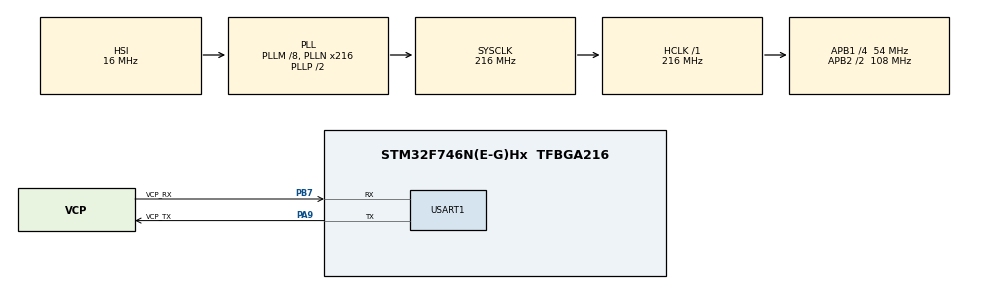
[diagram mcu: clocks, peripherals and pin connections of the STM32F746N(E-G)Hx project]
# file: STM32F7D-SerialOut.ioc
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Mcu.Family=STM32F7
Mcu.Name=STM32F746N(E-G)Hx
Mcu.Package=TFBGA216
NVIC.PriorityGroup=NVIC_PRIORITYGROUP_4
PA13.Mode=Trace-Asynchronous_SW
PA13.Signal=SYS_JTMS-SWDIO
PA14.Mode=Trace-Asynchronous_SW
PA14.Signal=SYS_JTCK-SWCLK
PA9.GPIO_Label=VCP_TX
PA9.Mode=Asynchronous
PA9.Signal=USART1_TX
PB3.Mode=Trace-Asynchronous_SW
PB3.Signal=SYS_JTDO-SWO
PB7.GPIO_Label=VCP_RX
PB7.Mode=Asynchronous
PB7.Signal=USART1_RX
ProjectManager.TargetToolchain=SW4STM32
RCC.AHBFreq_Value=216000000
RCC.APB1CLKDivider=RCC_HCLK_DIV4
RCC.APB1Freq_Value=54000000
RCC.APB1TimFreq_Value=108000000
RCC.APB2CLKDivider=RCC_HCLK_DIV2
RCC.APB2Freq_Value=108000000
RCC.APB2TimFreq_Value=216000000
RCC.CortexFreq_Value=216000000
RCC.HCLKFreq_Value=216000000
RCC.HSE_VALUE=25000000
RCC.HSI_VALUE=16000000
RCC.LSE_VALUE=32768
RCC.PLLM=8
RCC.PLLN=216
RCC.PLLQ=7
RCC.SYSCLKFreq_VALUE=216000000
RCC.SYSCLKSource=RCC_SYSCLKSOURCE_PLLCLK
RCC.USBFreq_Value=61714285.71428572
RCC.VCOOutputFreq_Value=432000000
board=STM32F746G-DISCO

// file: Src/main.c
/**
  ******************************************************************************
  * File Name          : main.c
  * Description        : Main program body
  ******************************************************************************
  *
  * COPYRIGHT(c) 2015 STMicroelectronics
  *
  * Redistribution and use in source and binary forms, with or without modification,
  * are permitted provided that the following conditions are met:
  *   1. Redistributions of source code must retain the above copyright notice,
  *      this list of conditions and the following disclaimer.
  *   2. Redistributions in binary form must reproduce the above copyright notice,
  *      this list of conditions and the following disclaimer in the documentation
  *      and/or other materials provided with the distribution.
  *   3. Neither the name of STMicroelectronics nor the names of its contributors
  *      may be used to endorse or promote products derived from this software
  *      without specific prior written permission.
  *
  * THIS SOFTWARE IS PROVIDED BY THE COPYRIGHT HOLDERS AND CONTRIBUTORS "AS IS"
  * AND ANY EXPRESS OR IMPLIED WARRANTIES, INCLUDING, BUT NOT LIMITED TO, THE
  * IMPLIED WARRANTIES OF MERCHANTABILITY AND FITNESS FOR A PARTICULAR PURPOSE ARE
  * DISCLAIMED. IN NO EVENT SHALL THE COPYRIGHT HOLDER OR CONTRIBUTORS BE LIABLE
  * FOR ANY DIRECT, INDIRECT, INCIDENTAL, SPECIAL, EXEMPLARY, OR CONSEQUENTIAL
  * DAMAGES (INCLUDING, BUT NOT LIMITED TO, PROCUREMENT OF SUBSTITUTE GOODS OR
  * SERVICES; LOSS OF USE, DATA, OR PROFITS; OR BUSINESS INTERRUPTION) HOWEVER
  * CAUSED AND ON ANY THEORY OF LIABILITY, WHETHER IN CONTRACT, STRICT LIABILITY,
  * OR TORT (INCLUDING NEGLIGENCE OR OTHERWISE) ARISING IN ANY WAY OUT OF THE USE
  * OF THIS SOFTWARE, EVEN IF ADVISED OF THE POSSIBILITY OF SUCH DAMAGE.
  *
  ******************************************************************************
  */
#include "stm32f7xx_hal.h"

UART_HandleTypeDef huart1;

/* USER CODE BEGIN PV */
/* Private variables ---------------------------------------------------------*/

/* USER CODE END PV */

void SystemClock_Config(void);
static void MX_GPIO_Init(void);
static void MX_USART1_UART_Init(void);

/* USER CODE BEGIN PFP */
/* Private function prototypes -----------------------------------------------*/

/* USER CODE END PFP */

int main(void)
{

  /* MCU Configuration----------------------------------------------------------*/

  /* Reset of all peripherals, Initializes the Flash interface and the Systick. */
  HAL_Init();

  /* Configure the system clock */
  SystemClock_Config();

  /* Initialize all configured peripherals */
  MX_GPIO_Init();
  MX_USART1_UART_Init();

  /* Infinite loop */
  /* USER CODE BEGIN WHILE */
  char output[3] = {'c', 'h', 'r'};
  int ch = 'c';
  while (1)
  {
  /* USER CODE END WHILE */
	  //HAL_UART_Transmit(&huart1, output, 3, 1000);
	  char str[32];
	  HAL_UART_Transmit(&huart1, (uint8_t *)&ch, 1, 0xFFFF); // As a pointer, with a length
  }

}

/** System Clock Configuration
*/
void SystemClock_Config(void)
{

  RCC_OscInitTypeDef RCC_OscInitStruct;
  RCC_ClkInitTypeDef RCC_ClkInitStruct;
  RCC_PeriphCLKInitTypeDef PeriphClkInitStruct;

  __PWR_CLK_ENABLE();

  __HAL_PWR_VOLTAGESCALING_CONFIG(PWR_REGULATOR_VOLTAGE_SCALE1);

  RCC_OscInitStruct.OscillatorType = RCC_OSCILLATORTYPE_HSI;
  RCC_OscInitStruct.HSIState = RCC_HSI_ON;
  RCC_OscInitStruct.HSICalibrationValue = 16;
  RCC_OscInitStruct.PLL.PLLState = RCC_PLL_ON;
  RCC_OscInitStruct.PLL.PLLSource = RCC_PLLSOURCE_HSI;
  RCC_OscInitStruct.PLL.PLLM = 8;
  RCC_OscInitStruct.PLL.PLLN = 216;
  RCC_OscInitStruct.PLL.PLLP = RCC_PLLP_DIV2;
  RCC_OscInitStruct.PLL.PLLQ = 7;
  HAL_RCC_OscConfig(&RCC_OscInitStruct);

  HAL_PWREx_ActivateOverDrive();

  RCC_ClkInitStruct.ClockType = RCC_CLOCKTYPE_HCLK|RCC_CLOCKTYPE_SYSCLK
                              |RCC_CLOCKTYPE_PCLK1|RCC_CLOCKTYPE_PCLK2;
  RCC_ClkInitStruct.SYSCLKSource = RCC_SYSCLKSOURCE_PLLCLK;
  RCC_ClkInitStruct.AHBCLKDivider = RCC_SYSCLK_DIV1;
  RCC_ClkInitStruct.APB1CLKDivider = RCC_HCLK_DIV4;
  RCC_ClkInitStruct.APB2CLKDivider = RCC_HCLK_DIV2;
  HAL_RCC_ClockConfig(&RCC_ClkInitStruct, FLASH_LATENCY_7);

  PeriphClkInitStruct.PeriphClockSelection = RCC_PERIPHCLK_USART1;
  PeriphClkInitStruct.Usart1ClockSelection = RCC_USART1CLKSOURCE_PCLK2;
  HAL_RCCEx_PeriphCLKConfig(&PeriphClkInitStruct);

  HAL_SYSTICK_Config(HAL_RCC_GetHCLKFreq()/1000);

  HAL_SYSTICK_CLKSourceConfig(SYSTICK_CLKSOURCE_HCLK);

  /* SysTick_IRQn interrupt configuration */
  HAL_NVIC_SetPriority(SysTick_IRQn, 0, 0);
}

/* USART1 init function */
void MX_USART1_UART_Init(void)
{

  huart1.Instance = USART1;
  huart1.Init.BaudRate = 115200;
  huart1.Init.WordLength = UART_WORDLENGTH_7B;
  huart1.Init.StopBits = UART_STOPBITS_1;
  huart1.Init.Parity = UART_PARITY_NONE;
  huart1.Init.Mode = UART_MODE_TX_RX;
  huart1.Init.HwFlowCtl = UART_HWCONTROL_NONE;
  huart1.Init.OverSampling = UART_OVERSAMPLING_16;
  huart1.Init.OneBitSampling = UART_ONEBIT_SAMPLING_DISABLED;
  huart1.AdvancedInit.AdvFeatureInit = UART_ADVFEATURE_NO_INIT;
  HAL_UART_Init(&huart1);

}

/** Configure pins as
        * Analog
        * Input
        * Output
        * EVENT_OUT
        * EXTI
*/
void MX_GPIO_Init(void)
{

  /* GPIO Ports Clock Enable */
  __GPIOB_CLK_ENABLE();
  __GPIOA_CLK_ENABLE();

}

/************************ (C) COPYRIGHT STMicroelectronics *****END OF FILE****/
